# MKE04Z1284 register map
Vendor: Freescale Semiconductor, Inc.; Series: Kinetis_E; File version: 1.6
CPU: CM0PLUS r0p0, little endian, no MPU, no FPU, VTOR, 2 interrupt priority bits
Registers are 32-bit, read-write, reset 0x0 unless marked. A register's access mark holds for its fields unless they carry their own. Offsets are from the block's base; [hi:lo] are bit positions; {n}, {i} and the like mark numbered series.

## SPI0 — Serial Peripheral Interface
Base 0x40076000; register names take the prefix SPI0_
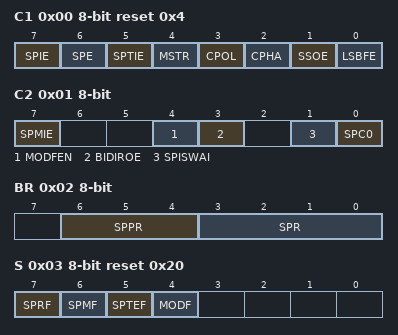
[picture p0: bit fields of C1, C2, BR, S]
0x00 C1 8-bit reset 0x4 — SPI Control Register 1
  [7] SPIE — SPI Interrupt Enable: for SPRF and MODF
    0=Interrupts from SPRF and MODF are inhibited-use polling; 1=Request a hardware interrupt when SPRF or MODF is 1
  [6] SPE — SPI System Enable
    0=SPI system inactive; 1=SPI system enabled
  [5] SPTIE — SPI Transmit Interrupt Enable
    0=Interrupts from SPTEF inhibited (use polling); 1=When SPTEF is 1, hardware interrupt requested
  [4] MSTR — Master/Slave Mode Select
    0=SPI module configured as a slave SPI device; 1=SPI module configured as a master SPI device
  [3] CPOL — Clock Polarity
    0=Active-high SPI clock (idles low); 1=Active-low SPI clock (idles high)
  [2] CPHA — Clock Phase
    0=First edge on SPSCK occurs at the middle of the first cycle of a data transfer; 1=First edge on SPSCK occurs at the start of the first cycle of a data transfer
  [1] SSOE — Slave Select Output Enable
    0=When C2[MODFEN] is 0: In master mode, SS pin function is general-purpose I/O (not SPI). In slave mode, SS pin function is slave select input. When C2[MODFEN] is 1: In master mode, SS pin function is SS input for mode fault. In slave mode, SS pin function is slave select input.; 1=When C2[MODFEN] is 0: In master mode, SS pin function is general-purpose I/O (not SPI). In slave mode, SS pin function is slave select input. When C2[MODFEN] is 1: In master mode, SS pin function is automatic SS output. In slave mode: SS pin function is slave select input.
  [0] LSBFE — LSB First (shifter direction)
    0=SPI serial data transfers start with the most significant bit; 1=SPI serial data transfers start with the least significant bit
0x01 C2 8-bit — SPI Control Register 2
  [7] SPMIE — SPI Match Interrupt Enable
    0=Interrupts from SPMF inhibited (use polling); 1=When SPMF is 1, requests a hardware interrupt
  [4] MODFEN — Master Mode-Fault Function Enable
    0=Mode fault function disabled, master SS pin reverts to general-purpose I/O not controlled by SPI; 1=Mode fault function enabled, master SS pin acts as the mode fault input or the slave select output
  [3] BIDIROE — Bidirectional Mode Output Enable
    0=Output driver disabled so SPI data I/O pin acts as an input; 1=SPI I/O pin enabled as an output
  [1] SPISWAI — SPI Stop in Wait Mode
    0=SPI clocks continue to operate in Wait mode; 1=SPI clocks stop when the MCU enters Wait mode
  [0] SPC0 — SPI Pin Control 0
    0=SPI uses separate pins for data input and data output (pin mode is normal). In master mode of operation: MISO is master in and MOSI is master out. In slave mode of operation: MISO is slave out and MOSI is slave in.; 1=SPI configured for single-wire bidirectional operation (pin mode is bidirectional). In master mode of operation: MISO is not used by SPI; MOSI is master in when BIDIROE is 0 or master I/O when BIDIROE is 1. In slave mode of operation: MISO is slave in when BIDIROE is 0 or slave I/O when BIDIROE is 1; MOSI is not used by SPI.
0x02 BR 8-bit — SPI Baud Rate Register
  [6:4] SPPR — SPI Baud Rate Prescale Divisor
    {v}=Baud rate prescaler divisor is {v+1} (v=0..7)
  [3:0] SPR — SPI Baud Rate Divisor
    0=Baud rate divisor is 2; 1=Baud rate divisor is 4; 2=Baud rate divisor is 8; 3=Baud rate divisor is 16; 4=Baud rate divisor is 32; 5=Baud rate divisor is 64; 6=Baud rate divisor is 128; 7=Baud rate divisor is 256; 8=Baud rate divisor is 512
0x03 S 8-bit reset 0x20 — SPI Status Register
  [7] SPRF ro — SPI Read Buffer Full Flag
    0=No data available in the receive data buffer; 1=Data available in the receive data buffer
  [6] SPMF — SPI Match Flag
    0=Value in the receive data buffer does not match the value in the M register; 1=Value in the receive data buffer matches the value in the M register
  [5] SPTEF ro — SPI Transmit Buffer Empty Flag
    0=SPI transmit buffer not empty; 1=SPI transmit buffer empty
  [4] MODF ro — Master Mode Fault Flag
    0=No mode fault error; 1=Mode fault error detected
0x05 D 8-bit — SPI Data Register
  [7:0] Bits — Data (low byte)
0x07 M 8-bit — SPI Match Register
  [7:0] Bits — Hardware compare value (low byte)

## SPI1 — Serial Peripheral Interface
Base 0x40077000; register names take the prefix SPI1_
Registers as SPI0.
